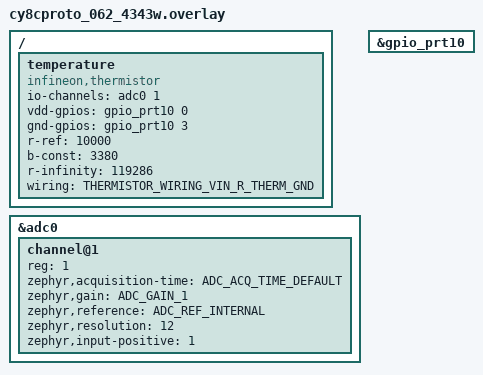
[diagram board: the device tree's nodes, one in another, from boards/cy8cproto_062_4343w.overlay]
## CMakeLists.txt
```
# SPDX-License-Identifier: Apache-2.0

cmake_minimum_required(VERSION 3.20.0)
find_package(Zephyr REQUIRED HINTS $ENV{ZEPHYR_BASE})
project(thermistor_sensor)

FILE(GLOB app_sources src/*.c)
target_sources(app PRIVATE ${app_sources})
```

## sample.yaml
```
sample:
  description: Illustrates how to use the thermistor to measure temperature
  name: Temperature (thermistor) sensor sample application
tests:
  sample.sensor.thermistor:
    depends_on: adc
    tags: sensors drivers temperature
    filter: dt_compat_enabled("infineon,thermistor")
    harness: sensor
```

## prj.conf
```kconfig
CONFIG_GPIO=y
CONFIG_SENSOR=y
CONFIG_ADC=y
CONFIG_PRINTK=y
CONFIG_CBPRINTF_FP_SUPPORT=y
CONFIG_NEWLIB_LIBC=y
CONFIG_NEWLIB_LIBC_FLOAT_PRINTF=y
```

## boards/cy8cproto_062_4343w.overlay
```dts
/*
 * Copyright (c) 2023 Cypress Semiconductor Corporation (an Infineon company) or
 * an affiliate of Cypress Semiconductor Corporation
 *
 * SPDX-License-Identifier: Apache-2.0
 */

#include <zephyr/dt-bindings/adc/adc.h>
#include <../drivers/sensor/thermistor/thermistor.h>

/ {
	temperature {
		compatible = "infineon,thermistor";
		io-channels = <&adc0 1>;
		vdd-gpios = <&gpio_prt10 0 GPIO_ACTIVE_HIGH>;
		gnd-gpios = <&gpio_prt10 3 GPIO_ACTIVE_HIGH>;
		r-ref = <10000>;
		b-const = <3380>;
		r-infinity = <119286>;
		wiring = <THERMISTOR_WIRING_VIN_R_THERM_GND>;
	};
};

&adc0 {
	status = "okay";
	#address-cells = <1>;
	#size-cells = <0>;

	channel@1 {
		reg = <1>;
		zephyr,acquisition-time = <ADC_ACQ_TIME_DEFAULT>;
		zephyr,gain = "ADC_GAIN_1";
		zephyr,reference = "ADC_REF_INTERNAL";
		zephyr,resolution = <12>;
		zephyr,input-positive = <1>;   /* P10.1 */
	};
};

&gpio_prt10 {
	status = "okay";
};
```

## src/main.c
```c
/*
 * Copyright (c) 2023 Cypress Semiconductor Corporation (an Infineon company) or
 * an affiliate of Cypress Semiconductor Corporation
 *
 * SPDX-License-Identifier: Apache-2.0
 */


#include <zephyr/kernel.h>
#include <zephyr/device.h>
#include <zephyr/drivers/sensor.h>
#include <zephyr/sys/printk.h>

int main(void)
{
	const struct device *const dev = DEVICE_DT_GET_ONE(infineon_thermistor);
	struct sensor_value value;
	int return_val;

	if (!device_is_ready(dev)) {
		printk("Thermistor is not ready\n");
		return -1;
	}

	printk("Thermistor example\n");

	while (true) {
		/* fetch sensor samples */
		return_val = sensor_sample_fetch(dev);
		if (return_val) {
			printk("Failed to fetch sample (%d)\n", return_val);
			continue;
		}

		return_val = sensor_channel_get(dev, SENSOR_CHAN_AMBIENT_TEMP, &value);
		if (return_val) {
			printk("Failed to get data (%d)\n", return_val);
			continue;
		}

		printk("Temperature: %.2f C\n\n", sensor_value_to_double(&value));

		k_sleep(K_MSEC(1000));
	}

	return 0;
}
```
